VERSION ""

NS_ :

BS_:

BU_: FrontBoard BackBoard Kvaser SteeringWheel TCU GPS ACULV Bamocar PDM

BO_ 3221225472 VECTOR__INDEPENDENT_SIG_MSG: 0 Vector__XXX
 SG_ NewSignal_0009 : 0|8@1+ (1,0) [0|0] "" Vector__XXX
 SG_ Frequency1 : 0|64@1- (1,0) [0|0] ""  FrontBoard,Kvaser,SteeringWheel
 SG_ Frequency2 : 64|64@1- (1,0) [0|0] ""  FrontBoard,Kvaser,SteeringWheel
 SG_ Frequency3 : 128|64@1- (1,0) [0|0] ""  FrontBoard,Kvaser,SteeringWheel
 SG_ Frequency4 : 192|64@1- (1,0) [0|0] ""  FrontBoard,Kvaser,SteeringWheel
 SG_ Frequency1 : 0|64@1- (1,0) [0|0] ""  BackBoard,Kvaser,SteeringWheel
 SG_ Frequency2 : 64|64@1- (1,0) [0|0] ""  BackBoard,Kvaser,SteeringWheel
 SG_ Frequency3 : 128|64@1- (1,0) [0|0] ""  BackBoard,Kvaser,SteeringWheel
 SG_ Frequency4 : 192|64@1- (1,0) [0|0] ""  BackBoard,Kvaser,SteeringWheel
 SG_ AccumulatorVoltage : 0|32@1- (1,0) [0|0] "" Vector__XXX
 SG_ TractiveVoltage : 0|32@1- (1,0) [0|0] "" Vector__XXX
 SG_ InputState_Diagnostics : 0|8@1+ (1,0) [0|0] "" Vector__XXX
 SG_ CompoundID : 0|8@1+ (1,0) [0|0] "" Vector__XXX
 SG_ DeviceInfo : 48|8@1+ (1,0) [0|0] "" Vector__XXX
 SG_ OutputLoad : 40|8@1+ (1,0) [0|0] "" Vector__XXX
 SG_ OutputCurrent : 32|8@1+ (1,0) [0|0] "" Vector__XXX
 SG_ OutputVoltage : 24|8@1+ (1,0) [0|0] "" Vector__XXX
 SG_ OutputState : 16|8@1+ (1,0) [0|0] "" Vector__XXX
 SG_ InputVoltage : 8|8@1+ (1,0) [0|0] "" Vector__XXX
 SG_ Byte2 : 0|8@1+ (1,0) [0|0] "" Vector__XXX
 SG_ Byte5 : 0|8@1+ (1,0) [0|0] "" Vector__XXX
 SG_ Byte4 : 0|8@1+ (1,0) [0|0] "" Vector__XXX
 SG_ Byte3 : 0|8@1+ (1,0) [0|0] "" Vector__XXX
 SG_ AirTemp : 0|32@1+ (1,0) [0|0] ""  Kvaser,SteeringWheel
 SG_ IGBTTemp : 0|32@1+ (1,0) [0|0] ""  Kvaser,SteeringWheel
 SG_ MotorTemp : 0|32@1+ (1,0) [0|0] ""  Kvaser,SteeringWheel

BO_ 259 FrontAnalog: 16 FrontBoard
 SG_ Analog1 : 0|16@1+ (1,0) [0|0] ""  FrontBoard,Kvaser,SteeringWheel
 SG_ Analog2 : 16|16@1+ (1,0) [0|0] ""  FrontBoard,Kvaser,SteeringWheel
 SG_ Analog3 : 32|16@1+ (1,0) [0|0] ""  FrontBoard,Kvaser,SteeringWheel
 SG_ Analog4 : 48|16@1+ (1,0) [0|0] ""  FrontBoard,Kvaser,SteeringWheel
 SG_ Analog5 : 64|16@1+ (1,0) [0|0] ""  FrontBoard,Kvaser,SteeringWheel
 SG_ Analog6 : 80|16@1+ (1,0) [0|0] ""  FrontBoard,Kvaser,SteeringWheel
 SG_ Analog7 : 96|16@1+ (1,0) [0|0] ""  FrontBoard,Kvaser,SteeringWheel
 SG_ Analog8 : 112|16@1+ (1,0) [0|0] ""  FrontBoard,Kvaser,SteeringWheel

BO_ 258 RearAnalog: 16 BackBoard
 SG_ Analog1 : 0|16@1+ (1,0) [0|0] ""  BackBoard,Kvaser,SteeringWheel
 SG_ Analog2 : 16|16@1+ (1,0) [0|0] ""  BackBoard,Kvaser,SteeringWheel
 SG_ Analog3 : 32|16@1+ (1,0) [0|0] ""  BackBoard,Kvaser,SteeringWheel
 SG_ Analog4 : 48|16@1+ (1,0) [0|0] ""  BackBoard,Kvaser,SteeringWheel
 SG_ Analog5 : 64|16@1+ (1,0) [0|0] ""  BackBoard,Kvaser,SteeringWheel
 SG_ Analog6 : 80|16@1+ (1,0) [0|0] ""  BackBoard,Kvaser,SteeringWheel
 SG_ Analog7 : 96|16@1+ (1,0) [0|0] ""  BackBoard,Kvaser,SteeringWheel
 SG_ Analog8 : 112|16@1+ (1,0) [0|0] ""  BackBoard,Kvaser,SteeringWheel

BO_ 1536 FrontAero: 16 FrontBoard
 SG_ Pressure1 : 0|24@1- (1,0) [0|0] ""  FrontBoard,Kvaser,SteeringWheel
 SG_ Pressure2 : 24|24@1- (1,0) [0|0] ""  FrontBoard,Kvaser,SteeringWheel
 SG_ Pressure3 : 48|24@1- (1,0) [0|0] ""  FrontBoard,Kvaser,SteeringWheel
 SG_ Temperature1 : 72|16@1- (1,0) [0|0] ""  FrontBoard,Kvaser,SteeringWheel
 SG_ Temperature2 : 88|16@1- (1,0) [0|0] ""  FrontBoard,Kvaser,SteeringWheel
 SG_ Temperature3 : 104|16@1- (1,0) [0|0] ""  FrontBoard,Kvaser,SteeringWheel

BO_ 1537 RearAero: 16 BackBoard
 SG_ Pressure1 : 0|24@1- (1,0) [0|0] ""  BackBoard,SteeringWheel,Kvaser
 SG_ Pressure2 : 24|24@1- (1,0) [0|0] ""  BackBoard,SteeringWheel,Kvaser
 SG_ Pressure3 : 48|24@1- (1,0) [0|0] ""  BackBoard,SteeringWheel,Kvaser
 SG_ Temperature1 : 72|16@1- (1,0) [0|0] ""  BackBoard,SteeringWheel,Kvaser
 SG_ Temperature2 : 88|16@1- (1,0) [0|0] ""  BackBoard,SteeringWheel,Kvaser
 SG_ Temperature3 : 104|16@1- (1,0) [0|0] ""  BackBoard,SteeringWheel,Kvaser

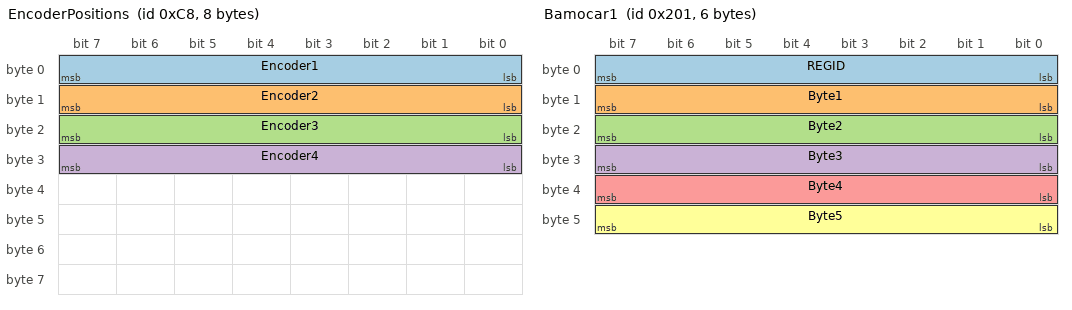
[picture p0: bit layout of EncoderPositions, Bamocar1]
BO_ 200 EncoderPositions: 8 SteeringWheel
 SG_ Encoder1 : 0|8@1+ (1,0) [0|0] ""  Kvaser
 SG_ Encoder2 : 8|8@1+ (1,0) [0|0] ""  Kvaser
 SG_ Encoder3 : 16|8@1+ (1,0) [0|0] ""  Kvaser
 SG_ Encoder4 : 24|8@1+ (1,0) [0|0] ""  Kvaser

BO_ 1552 FrontStrainGauges1: 20 FrontBoard
 SG_ Gauge1 : 0|24@1+ (1,0) [0|0] ""  Kvaser
 SG_ Gauge2 : 24|24@1+ (1,0) [0|0] ""  Kvaser
 SG_ Gauge3 : 48|24@1+ (1,0) [0|0] ""  Kvaser
 SG_ Gauge4 : 72|24@1+ (1,0) [0|0] ""  Kvaser
 SG_ Gauge5 : 96|24@1+ (1,0) [0|0] ""  Kvaser
 SG_ Gauge6 : 120|24@1+ (1,0) [0|0] ""  Kvaser

BO_ 1553 FrontStrainGauges2: 20 FrontBoard
 SG_ Gauge1 : 0|24@1+ (1,0) [0|0] ""  Kvaser
 SG_ Gauge2 : 24|24@1+ (1,0) [0|0] ""  Kvaser
 SG_ Gauge3 : 48|24@1+ (1,0) [0|0] ""  Kvaser
 SG_ Gauge4 : 72|24@1+ (1,0) [0|0] ""  Kvaser
 SG_ Gauge5 : 96|24@1+ (1,0) [0|0] ""  Kvaser
 SG_ Gauge6 : 120|24@1+ (1,0) [0|0] ""  Kvaser

BO_ 1554 RearStrainGauges1: 20 BackBoard
 SG_ Gauge1 : 0|24@1+ (1,0) [0|0] ""  Kvaser
 SG_ Gauge2 : 24|24@1+ (1,0) [0|0] ""  Kvaser
 SG_ Gauge3 : 48|24@1+ (1,0) [0|0] ""  Kvaser
 SG_ Gauge4 : 72|24@1+ (1,0) [0|0] ""  Kvaser
 SG_ Gauge5 : 96|24@1+ (1,0) [0|0] ""  Kvaser
 SG_ Gauge6 : 120|24@1+ (1,0) [0|0] ""  Kvaser

BO_ 1555 RearStrainGauges2: 20 BackBoard
 SG_ Gauge1 : 0|24@1+ (1,0) [0|0] ""  Kvaser
 SG_ Gauge2 : 24|24@1+ (1,0) [0|0] ""  Kvaser
 SG_ Gauge3 : 48|24@1+ (1,0) [0|0] ""  Kvaser
 SG_ Gauge4 : 72|24@1+ (1,0) [0|0] ""  Kvaser
 SG_ Gauge5 : 96|24@1+ (1,0) [0|0] ""  Kvaser
 SG_ Gauge6 : 120|24@1+ (1,0) [0|0] ""  Kvaser

BO_ 80 GPSBestPos: 48 GPS
 SG_ Latitude : 0|64@1- (1,0) [0|0] ""  Kvaser,SteeringWheel
 SG_ Longitude : 64|64@1- (1,0) [0|0] ""  Kvaser,SteeringWheel
 SG_ Altitude : 128|64@1- (1,0) [0|0] ""  Kvaser,SteeringWheel
 SG_ stdLatitude : 192|64@1- (1,0) [0|0] ""  Kvaser,SteeringWheel
 SG_ stdLongitude : 256|64@1- (1,0) [0|0] ""  Kvaser,SteeringWheel
 SG_ stdAltitude : 320|64@1- (1,0) [0|0] ""  Kvaser,SteeringWheel

BO_ 101 FrontFrequency: 16 FrontBoard
 SG_ Freq1 : 0|32@1- (1,0) [0|0] ""  Kvaser,SteeringWheel
 SG_ Freq2 : 32|32@1- (1,0) [0|0] ""  Kvaser,SteeringWheel
 SG_ Freq3 : 64|32@1- (1,0) [0|0] ""  Kvaser,SteeringWheel
 SG_ Freq4 : 96|32@1- (1,0) [0|0] ""  Kvaser,SteeringWheel

BO_ 102 RearFrequency: 16 BackBoard
 SG_ Freq1 : 0|32@1- (1,0) [0|0] ""  Kvaser,SteeringWheel
 SG_ Freq2 : 32|32@1- (1,0) [0|0] ""  Kvaser,SteeringWheel
 SG_ Freq3 : 64|32@1- (1,0) [0|0] ""  Kvaser,SteeringWheel
 SG_ Freq4 : 96|32@1- (1,0) [0|0] ""  Kvaser,SteeringWheel

BO_ 513 Bamocar1: 6 TCU
 SG_ REGID : 0|8@1- (1,0) [0|0] ""  Kvaser,SteeringWheel
 SG_ Byte1 : 8|8@1+ (1,0) [0|0] ""  Kvaser,SteeringWheel
 SG_ Byte2 : 16|8@1+ (1,0) [0|0] ""  Kvaser,SteeringWheel
 SG_ Byte3 : 24|8@1+ (1,0) [0|0] ""  Kvaser,SteeringWheel
 SG_ Byte4 : 32|8@1+ (1,0) [0|0] ""  Kvaser,SteeringWheel
 SG_ Byte5 : 40|8@1+ (1,0) [0|0] ""  Kvaser,SteeringWheel

BO_ 50 CellVoltage1: 64 ACULV
 SG_ Cell1 : 0|32@1- (1,0) [0|0] ""  Kvaser,SteeringWheel
 SG_ Cell2 : 32|32@1- (1,0) [0|0] ""  Kvaser,SteeringWheel
 SG_ Cell3 : 64|32@1- (1,0) [0|0] ""  Kvaser,SteeringWheel
 SG_ Cell4 : 96|32@1- (1,0) [0|0] ""  Kvaser,SteeringWheel
 SG_ Cell5 : 128|32@1- (1,0) [0|0] ""  Kvaser,SteeringWheel
 SG_ Cell6 : 160|32@1- (1,0) [0|0] ""  Kvaser,SteeringWheel
 SG_ Cell7 : 192|32@1- (1,0) [0|0] ""  Kvaser,SteeringWheel
 SG_ Cell8 : 224|32@1- (1,0) [0|0] ""  Kvaser,SteeringWheel
 SG_ Cell9 : 256|32@1- (1,0) [0|0] ""  Kvaser,SteeringWheel
 SG_ Cell10 : 288|32@1- (1,0) [0|0] ""  Kvaser,SteeringWheel
 SG_ Cell11 : 320|32@1- (1,0) [0|0] ""  Kvaser,SteeringWheel
 SG_ Cell12 : 352|32@1- (1,0) [0|0] ""  Kvaser,SteeringWheel
 SG_ Cell13 : 384|32@1- (1,0) [0|0] ""  Kvaser,SteeringWheel
 SG_ Cell14 : 416|32@1- (1,0) [0|0] ""  Kvaser,SteeringWheel
 SG_ Cell15 : 448|32@1- (1,0) [0|0] ""  Kvaser,SteeringWheel
 SG_ Cell16 : 480|32@1- (1,0) [0|0] ""  Kvaser,SteeringWheel

BO_ 51 CellVoltage2: 64 ACULV
 SG_ Cell1 : 0|32@1- (1,0) [0|0] ""  Kvaser,SteeringWheel
 SG_ Cell2 : 32|32@1- (1,0) [0|0] ""  Kvaser,SteeringWheel
 SG_ Cell3 : 64|32@1- (1,0) [0|0] ""  Kvaser,SteeringWheel
 SG_ Cell4 : 96|32@1- (1,0) [0|0] ""  Kvaser,SteeringWheel
 SG_ Cell5 : 128|32@1- (1,0) [0|0] ""  Kvaser,SteeringWheel
 SG_ Cell6 : 160|32@1- (1,0) [0|0] ""  Kvaser,SteeringWheel
 SG_ Cell7 : 192|32@1- (1,0) [0|0] ""  Kvaser,SteeringWheel
 SG_ Cell8 : 224|32@1- (1,0) [0|0] ""  Kvaser,SteeringWheel
 SG_ Cell9 : 256|32@1- (1,0) [0|0] ""  Kvaser,SteeringWheel
 SG_ Cell10 : 288|32@1- (1,0) [0|0] ""  Kvaser,SteeringWheel
 SG_ Cell11 : 320|32@1- (1,0) [0|0] ""  Kvaser,SteeringWheel
 SG_ Cell12 : 352|32@1- (1,0) [0|0] ""  Kvaser,SteeringWheel
 SG_ Cell13 : 384|32@1- (1,0) [0|0] ""  Kvaser,SteeringWheel
 SG_ Cell14 : 416|32@1- (1,0) [0|0] ""  Kvaser,SteeringWheel
 SG_ Cell15 : 448|32@1- (1,0) [0|0] ""  Kvaser,SteeringWheel
 SG_ Cell16 : 480|32@1- (1,0) [0|0] ""  Kvaser,SteeringWheel

BO_ 52 CellVoltage3: 64 ACULV
 SG_ Cell1 : 0|32@1- (1,0) [0|0] ""  Kvaser,SteeringWheel
 SG_ Cell2 : 32|32@1- (1,0) [0|0] ""  Kvaser,SteeringWheel
 SG_ Cell3 : 64|32@1- (1,0) [0|0] ""  Kvaser,SteeringWheel
 SG_ Cell4 : 96|32@1- (1,0) [0|0] ""  Kvaser,SteeringWheel
 SG_ Cell5 : 128|32@1- (1,0) [0|0] ""  Kvaser,SteeringWheel
 SG_ Cell6 : 160|32@1- (1,0) [0|0] ""  Kvaser,SteeringWheel
 SG_ Cell7 : 192|32@1- (1,0) [0|0] ""  Kvaser,SteeringWheel
 SG_ Cell8 : 224|32@1- (1,0) [0|0] ""  Kvaser,SteeringWheel
 SG_ Cell9 : 256|32@1- (1,0) [0|0] ""  Kvaser,SteeringWheel
 SG_ Cell10 : 288|32@1- (1,0) [0|0] ""  Kvaser,SteeringWheel
 SG_ Cell11 : 320|32@1- (1,0) [0|0] ""  Kvaser,SteeringWheel
 SG_ Cell12 : 352|32@1- (1,0) [0|0] ""  Kvaser,SteeringWheel
 SG_ Cell13 : 384|32@1- (1,0) [0|0] ""  Kvaser,SteeringWheel
 SG_ Cell14 : 416|32@1- (1,0) [0|0] ""  Kvaser,SteeringWheel
 SG_ Cell15 : 448|32@1- (1,0) [0|0] ""  Kvaser,SteeringWheel
 SG_ Cell16 : 480|32@1- (1,0) [0|0] ""  Kvaser,SteeringWheel

BO_ 53 CellVoltage4: 64 ACULV
 SG_ Cell1 : 0|32@1- (1,0) [0|0] ""  Kvaser,SteeringWheel
 SG_ Cell2 : 32|32@1- (1,0) [0|0] ""  Kvaser,SteeringWheel
 SG_ Cell3 : 64|32@1- (1,0) [0|0] ""  Kvaser,SteeringWheel
 SG_ Cell4 : 96|32@1- (1,0) [0|0] ""  Kvaser,SteeringWheel
 SG_ Cell5 : 128|32@1- (1,0) [0|0] ""  Kvaser,SteeringWheel
 SG_ Cell6 : 160|32@1- (1,0) [0|0] ""  Kvaser,SteeringWheel
 SG_ Cell7 : 192|32@1- (1,0) [0|0] ""  Kvaser,SteeringWheel
 SG_ Cell8 : 224|32@1- (1,0) [0|0] ""  Kvaser,SteeringWheel
 SG_ Cell9 : 256|32@1- (1,0) [0|0] ""  Kvaser,SteeringWheel
 SG_ Cell10 : 288|32@1- (1,0) [0|0] ""  Kvaser,SteeringWheel
 SG_ Cell11 : 320|32@1- (1,0) [0|0] ""  Kvaser,SteeringWheel
 SG_ Cell12 : 352|32@1- (1,0) [0|0] ""  Kvaser,SteeringWheel
 SG_ Cell13 : 384|32@1- (1,0) [0|0] ""  Kvaser,SteeringWheel
 SG_ Cell14 : 416|32@1- (1,0) [0|0] ""  Kvaser,SteeringWheel
 SG_ Cell15 : 448|32@1- (1,0) [0|0] ""  Kvaser,SteeringWheel
 SG_ Cell16 : 480|32@1- (1,0) [0|0] ""  Kvaser,SteeringWheel

BO_ 54 CellVoltage5: 64 ACULV
 SG_ Cell1 : 0|32@1- (1,0) [0|0] ""  Kvaser,SteeringWheel
 SG_ Cell2 : 32|32@1- (1,0) [0|0] ""  Kvaser,SteeringWheel
 SG_ Cell3 : 64|32@1- (1,0) [0|0] ""  Kvaser,SteeringWheel
 SG_ Cell4 : 96|32@1- (1,0) [0|0] ""  Kvaser,SteeringWheel
 SG_ Cell5 : 128|32@1- (1,0) [0|0] ""  Kvaser,SteeringWheel
 SG_ Cell6 : 160|32@1- (1,0) [0|0] ""  Kvaser,SteeringWheel
 SG_ Cell7 : 192|32@1- (1,0) [0|0] ""  Kvaser,SteeringWheel
 SG_ Cell8 : 224|32@1- (1,0) [0|0] ""  Kvaser,SteeringWheel
 SG_ Cell9 : 256|32@1- (1,0) [0|0] ""  Kvaser,SteeringWheel
 SG_ Cell10 : 288|32@1- (1,0) [0|0] ""  Kvaser,SteeringWheel
 SG_ Cell11 : 320|32@1- (1,0) [0|0] ""  Kvaser,SteeringWheel
 SG_ Cell12 : 352|32@1- (1,0) [0|0] ""  Kvaser,SteeringWheel
 SG_ Cell13 : 384|32@1- (1,0) [0|0] ""  Kvaser,SteeringWheel
 SG_ Cell14 : 416|32@1- (1,0) [0|0] ""  Kvaser,SteeringWheel
 SG_ Cell15 : 448|32@1- (1,0) [0|0] ""  Kvaser,SteeringWheel
 SG_ Cell16 : 480|32@1- (1,0) [0|0] ""  Kvaser,SteeringWheel

BO_ 55 CellVoltage6: 64 ACULV
 SG_ Cell1 : 0|32@1- (1,0) [0|0] ""  Kvaser,SteeringWheel
 SG_ Cell2 : 32|32@1- (1,0) [0|0] ""  Kvaser,SteeringWheel
 SG_ Cell3 : 64|32@1- (1,0) [0|0] ""  Kvaser,SteeringWheel
 SG_ Cell4 : 96|32@1- (1,0) [0|0] ""  Kvaser,SteeringWheel
 SG_ Cell5 : 128|32@1- (1,0) [0|0] ""  Kvaser,SteeringWheel
 SG_ Cell6 : 160|32@1- (1,0) [0|0] ""  Kvaser,SteeringWheel
 SG_ Cell7 : 192|32@1- (1,0) [0|0] ""  Kvaser,SteeringWheel
 SG_ Cell8 : 224|32@1- (1,0) [0|0] ""  Kvaser,SteeringWheel
 SG_ Cell9 : 256|32@1- (1,0) [0|0] ""  Kvaser,SteeringWheel
 SG_ Cell10 : 288|32@1- (1,0) [0|0] ""  Kvaser,SteeringWheel
 SG_ Cell11 : 320|32@1- (1,0) [0|0] ""  Kvaser,SteeringWheel
 SG_ Cell12 : 352|32@1- (1,0) [0|0] ""  Kvaser,SteeringWheel
 SG_ Cell13 : 384|32@1- (1,0) [0|0] ""  Kvaser,SteeringWheel
 SG_ Cell14 : 416|32@1- (1,0) [0|0] ""  Kvaser,SteeringWheel
 SG_ Cell15 : 448|32@1- (1,0) [0|0] ""  Kvaser,SteeringWheel
 SG_ Cell16 : 480|32@1- (1,0) [0|0] ""  Kvaser,SteeringWheel

BO_ 56 CellVoltage7: 64 ACULV
 SG_ Cell1 : 0|32@1- (1,0) [0|0] ""  Kvaser,SteeringWheel
 SG_ Cell2 : 32|32@1- (1,0) [0|0] ""  Kvaser,SteeringWheel
 SG_ Cell3 : 64|32@1- (1,0) [0|0] ""  Kvaser,SteeringWheel
 SG_ Cell4 : 96|32@1- (1,0) [0|0] ""  Kvaser,SteeringWheel
 SG_ Cell5 : 128|32@1- (1,0) [0|0] ""  Kvaser,SteeringWheel
 SG_ Cell6 : 160|32@1- (1,0) [0|0] ""  Kvaser,SteeringWheel
 SG_ Cell7 : 192|32@1- (1,0) [0|0] ""  Kvaser,SteeringWheel
 SG_ Cell8 : 224|32@1- (1,0) [0|0] ""  Kvaser,SteeringWheel
 SG_ Cell9 : 256|32@1- (1,0) [0|0] ""  Kvaser,SteeringWheel
 SG_ Cell10 : 288|32@1- (1,0) [0|0] ""  Kvaser,SteeringWheel
 SG_ Cell11 : 320|32@1- (1,0) [0|0] ""  Kvaser,SteeringWheel
 SG_ Cell12 : 352|32@1- (1,0) [0|0] ""  Kvaser,SteeringWheel
 SG_ Cell13 : 384|32@1- (1,0) [0|0] ""  Kvaser,SteeringWheel
 SG_ Cell14 : 416|32@1- (1,0) [0|0] ""  Kvaser,SteeringWheel
 SG_ Cell15 : 448|32@1- (1,0) [0|0] ""  Kvaser,SteeringWheel
 SG_ Cell16 : 480|32@1- (1,0) [0|0] ""  Kvaser,SteeringWheel

BO_ 57 CellVoltage8: 64 ACULV
 SG_ Cell1 : 0|32@1- (1,0) [0|0] ""  Kvaser,SteeringWheel
 SG_ Cell2 : 32|32@1- (1,0) [0|0] ""  Kvaser,SteeringWheel
 SG_ Cell3 : 64|32@1- (1,0) [0|0] ""  Kvaser,SteeringWheel
 SG_ Cell4 : 96|32@1- (1,0) [0|0] ""  Kvaser,SteeringWheel
 SG_ Cell5 : 128|32@1- (1,0) [0|0] ""  Kvaser,SteeringWheel
 SG_ Cell6 : 160|32@1- (1,0) [0|0] ""  Kvaser,SteeringWheel
 SG_ Cell7 : 192|32@1- (1,0) [0|0] ""  Kvaser,SteeringWheel
 SG_ Cell8 : 224|32@1- (1,0) [0|0] ""  Kvaser,SteeringWheel
 SG_ Cell9 : 256|32@1- (1,0) [0|0] ""  Kvaser,SteeringWheel
 SG_ Cell10 : 288|32@1- (1,0) [0|0] ""  Kvaser,SteeringWheel
 SG_ Cell11 : 320|32@1- (1,0) [0|0] ""  Kvaser,SteeringWheel
 SG_ Cell12 : 352|32@1- (1,0) [0|0] ""  Kvaser,SteeringWheel
 SG_ Cell13 : 384|32@1- (1,0) [0|0] ""  Kvaser,SteeringWheel
 SG_ Cell14 : 416|32@1- (1,0) [0|0] ""  Kvaser,SteeringWheel
 SG_ Cell15 : 448|32@1- (1,0) [0|0] ""  Kvaser,SteeringWheel
 SG_ Cell16 : 480|32@1- (1,0) [0|0] ""  Kvaser,SteeringWheel

BO_ 60 Thermistor1: 64 ACULV
 SG_ Therm1 : 0|32@1- (1,0) [0|0] ""  Kvaser,SteeringWheel
 SG_ Therm2 : 32|32@1- (1,0) [0|0] ""  Kvaser,SteeringWheel
 SG_ Therm3 : 64|32@1- (1,0) [0|0] ""  Kvaser,SteeringWheel
 SG_ Therm4 : 96|32@1- (1,0) [0|0] ""  Kvaser,SteeringWheel
 SG_ Therm5 : 128|32@1- (1,0) [0|0] ""  Kvaser,SteeringWheel
 SG_ Therm6 : 160|32@1- (1,0) [0|0] ""  Kvaser,SteeringWheel
 SG_ Therm7 : 192|32@1- (1,0) [0|0] ""  Kvaser,SteeringWheel
 SG_ Therm8 : 224|32@1- (1,0) [0|0] ""  Kvaser,SteeringWheel
 SG_ Therm9 : 256|32@1- (1,0) [0|0] ""  Kvaser,SteeringWheel
 SG_ Therm10 : 288|32@1- (1,0) [0|0] ""  Kvaser,SteeringWheel
 SG_ Therm11 : 320|32@1- (1,0) [0|0] ""  Kvaser,SteeringWheel
 SG_ Therm12 : 352|32@1- (1,0) [0|0] ""  Kvaser,SteeringWheel
 SG_ Therm13 : 384|32@1- (1,0) [0|0] ""  Kvaser,SteeringWheel
 SG_ Therm14 : 416|32@1- (1,0) [0|0] ""  Kvaser,SteeringWheel
 SG_ Therm15 : 448|32@1- (1,0) [0|0] ""  Kvaser,SteeringWheel
 SG_ Therm16 : 480|32@1- (1,0) [0|0] ""  Kvaser,SteeringWheel

BO_ 61 Thermistor2: 64 ACULV
 SG_ Therm1 : 0|32@1- (1,0) [0|0] ""  Kvaser,SteeringWheel
 SG_ Therm2 : 32|32@1- (1,0) [0|0] ""  Kvaser,SteeringWheel
 SG_ Therm3 : 64|32@1- (1,0) [0|0] ""  Kvaser,SteeringWheel
 SG_ Therm4 : 96|32@1- (1,0) [0|0] ""  Kvaser,SteeringWheel
 SG_ Therm5 : 128|32@1- (1,0) [0|0] ""  Kvaser,SteeringWheel
 SG_ Therm6 : 160|32@1- (1,0) [0|0] ""  Kvaser,SteeringWheel
 SG_ Therm7 : 192|32@1- (1,0) [0|0] ""  Kvaser,SteeringWheel
 SG_ Therm8 : 224|32@1- (1,0) [0|0] ""  Kvaser,SteeringWheel
 SG_ Therm9 : 256|32@1- (1,0) [0|0] ""  Kvaser,SteeringWheel
 SG_ Therm10 : 288|32@1- (1,0) [0|0] ""  Kvaser,SteeringWheel
 SG_ Therm11 : 320|32@1- (1,0) [0|0] ""  Kvaser,SteeringWheel
 SG_ Therm12 : 352|32@1- (1,0) [0|0] ""  Kvaser,SteeringWheel
 SG_ Therm13 : 384|32@1- (1,0) [0|0] ""  Kvaser,SteeringWheel
 SG_ Therm14 : 416|32@1- (1,0) [0|0] ""  Kvaser,SteeringWheel
 SG_ Therm15 : 448|32@1- (1,0) [0|0] ""  Kvaser,SteeringWheel
 SG_ Therm16 : 480|32@1- (1,0) [0|0] ""  Kvaser,SteeringWheel

BO_ 62 Thermistor3: 64 ACULV
 SG_ Therm1 : 0|32@1- (1,0) [0|0] ""  Kvaser,SteeringWheel
 SG_ Therm2 : 32|32@1- (1,0) [0|0] ""  Kvaser,SteeringWheel
 SG_ Therm3 : 64|32@1- (1,0) [0|0] ""  Kvaser,SteeringWheel
 SG_ Therm4 : 96|32@1- (1,0) [0|0] ""  Kvaser,SteeringWheel
 SG_ Therm5 : 128|32@1- (1,0) [0|0] ""  Kvaser,SteeringWheel
 SG_ Therm6 : 160|32@1- (1,0) [0|0] ""  Kvaser,SteeringWheel
 SG_ Therm7 : 192|32@1- (1,0) [0|0] ""  Kvaser,SteeringWheel
 SG_ Therm8 : 224|32@1- (1,0) [0|0] ""  Kvaser,SteeringWheel
 SG_ Therm9 : 256|32@1- (1,0) [0|0] ""  Kvaser,SteeringWheel
 SG_ Therm10 : 288|32@1- (1,0) [0|0] ""  Kvaser,SteeringWheel
 SG_ Therm11 : 320|32@1- (1,0) [0|0] ""  Kvaser,SteeringWheel
 SG_ Therm12 : 352|32@1- (1,0) [0|0] ""  Kvaser,SteeringWheel
 SG_ Therm13 : 384|32@1- (1,0) [0|0] ""  Kvaser,SteeringWheel
 SG_ Therm14 : 416|32@1- (1,0) [0|0] ""  Kvaser,SteeringWheel
 SG_ Therm15 : 448|32@1- (1,0) [0|0] ""  Kvaser,SteeringWheel
 SG_ Therm16 : 480|32@1- (1,0) [0|0] ""  Kvaser,SteeringWheel

BO_ 63 Thermistor4: 64 ACULV
 SG_ Therm1 : 0|32@1- (1,0) [0|0] ""  Kvaser,SteeringWheel
 SG_ Therm2 : 32|32@1- (1,0) [0|0] ""  Kvaser,SteeringWheel
 SG_ Therm3 : 64|32@1- (1,0) [0|0] ""  Kvaser,SteeringWheel
 SG_ Therm4 : 96|32@1- (1,0) [0|0] ""  Kvaser,SteeringWheel
 SG_ Therm5 : 128|32@1- (1,0) [0|0] ""  Kvaser,SteeringWheel
 SG_ Therm6 : 160|32@1- (1,0) [0|0] ""  Kvaser,SteeringWheel
 SG_ Therm7 : 192|32@1- (1,0) [0|0] ""  Kvaser,SteeringWheel
 SG_ Therm8 : 224|32@1- (1,0) [0|0] ""  Kvaser,SteeringWheel
 SG_ Therm9 : 256|32@1- (1,0) [0|0] ""  Kvaser,SteeringWheel
 SG_ Therm10 : 288|32@1- (1,0) [0|0] ""  Kvaser,SteeringWheel
 SG_ Therm11 : 320|32@1- (1,0) [0|0] ""  Kvaser,SteeringWheel
 SG_ Therm12 : 352|32@1- (1,0) [0|0] ""  Kvaser,SteeringWheel
 SG_ Therm13 : 384|32@1- (1,0) [0|0] ""  Kvaser,SteeringWheel
 SG_ Therm14 : 416|32@1- (1,0) [0|0] ""  Kvaser,SteeringWheel
 SG_ Therm15 : 448|32@1- (1,0) [0|0] ""  Kvaser,SteeringWheel
 SG_ Therm16 : 480|32@1- (1,0) [0|0] ""  Kvaser,SteeringWheel

BO_ 64 Thermistor5: 64 ACULV
 SG_ Therm1 : 0|32@1- (1,0) [0|0] ""  Kvaser,SteeringWheel
 SG_ Therm2 : 32|32@1- (1,0) [0|0] ""  Kvaser,SteeringWheel
 SG_ Therm3 : 64|32@1- (1,0) [0|0] ""  Kvaser,SteeringWheel
 SG_ Therm4 : 96|32@1- (1,0) [0|0] ""  Kvaser,SteeringWheel
 SG_ Therm5 : 128|32@1- (1,0) [0|0] ""  Kvaser,SteeringWheel
 SG_ Therm6 : 160|32@1- (1,0) [0|0] ""  Kvaser,SteeringWheel
 SG_ Therm7 : 192|32@1- (1,0) [0|0] ""  Kvaser,SteeringWheel
 SG_ Therm8 : 224|32@1- (1,0) [0|0] ""  Kvaser,SteeringWheel
 SG_ Therm9 : 256|32@1- (1,0) [0|0] ""  Kvaser,SteeringWheel
 SG_ Therm10 : 288|32@1- (1,0) [0|0] ""  Kvaser,SteeringWheel
 SG_ Therm11 : 320|32@1- (1,0) [0|0] ""  Kvaser,SteeringWheel
 SG_ Therm12 : 352|32@1- (1,0) [0|0] ""  Kvaser,SteeringWheel
 SG_ Therm13 : 384|32@1- (1,0) [0|0] ""  Kvaser,SteeringWheel
 SG_ Therm14 : 416|32@1- (1,0) [0|0] ""  Kvaser,SteeringWheel
 SG_ Therm15 : 448|32@1- (1,0) [0|0] ""  Kvaser,SteeringWheel
 SG_ Therm16 : 480|32@1- (1,0) [0|0] ""  Kvaser,SteeringWheel

BO_ 65 Thermistor6: 64 ACULV
 SG_ Therm1 : 0|32@1- (1,0) [0|0] ""  Kvaser,SteeringWheel
 SG_ Therm2 : 32|32@1- (1,0) [0|0] ""  Kvaser,SteeringWheel
 SG_ Therm3 : 64|32@1- (1,0) [0|0] ""  Kvaser,SteeringWheel
 SG_ Therm4 : 96|32@1- (1,0) [0|0] ""  Kvaser,SteeringWheel
 SG_ Therm5 : 128|32@1- (1,0) [0|0] ""  Kvaser,SteeringWheel
 SG_ Therm6 : 160|32@1- (1,0) [0|0] ""  Kvaser,SteeringWheel
 SG_ Therm7 : 192|32@1- (1,0) [0|0] ""  Kvaser,SteeringWheel
 SG_ Therm8 : 224|32@1- (1,0) [0|0] ""  Kvaser,SteeringWheel
 SG_ Therm9 : 256|32@1- (1,0) [0|0] ""  Kvaser,SteeringWheel
 SG_ Therm10 : 288|32@1- (1,0) [0|0] ""  Kvaser,SteeringWheel
 SG_ Therm11 : 320|32@1- (1,0) [0|0] ""  Kvaser,SteeringWheel
 SG_ Therm12 : 352|32@1- (1,0) [0|0] ""  Kvaser,SteeringWheel
 SG_ Therm13 : 384|32@1- (1,0) [0|0] ""  Kvaser,SteeringWheel
 SG_ Therm14 : 416|32@1- (1,0) [0|0] ""  Kvaser,SteeringWheel
 SG_ Therm15 : 448|32@1- (1,0) [0|0] ""  Kvaser,SteeringWheel
 SG_ Therm16 : 480|32@1- (1,0) [0|0] ""  Kvaser,SteeringWheel

BO_ 66 Thermistor7: 64 ACULV
 SG_ Therm1 : 0|32@1- (1,0) [0|0] ""  Kvaser,SteeringWheel
 SG_ Therm2 : 32|32@1- (1,0) [0|0] ""  Kvaser,SteeringWheel
 SG_ Therm3 : 64|32@1- (1,0) [0|0] ""  Kvaser,SteeringWheel
 SG_ Therm4 : 96|32@1- (1,0) [0|0] ""  Kvaser,SteeringWheel
 SG_ Therm5 : 128|32@1- (1,0) [0|0] ""  Kvaser,SteeringWheel
 SG_ Therm6 : 160|32@1- (1,0) [0|0] ""  Kvaser,SteeringWheel
 SG_ Therm7 : 192|32@1- (1,0) [0|0] ""  Kvaser,SteeringWheel
 SG_ Therm8 : 224|32@1- (1,0) [0|0] ""  Kvaser,SteeringWheel
 SG_ Therm9 : 256|32@1- (1,0) [0|0] ""  Kvaser,SteeringWheel
 SG_ Therm10 : 288|32@1- (1,0) [0|0] ""  Kvaser,SteeringWheel
 SG_ Therm11 : 320|32@1- (1,0) [0|0] ""  Kvaser,SteeringWheel
 SG_ Therm12 : 352|32@1- (1,0) [0|0] ""  Kvaser,SteeringWheel
 SG_ Therm13 : 384|32@1- (1,0) [0|0] ""  Kvaser,SteeringWheel
 SG_ Therm14 : 416|32@1- (1,0) [0|0] ""  Kvaser,SteeringWheel
 SG_ Therm15 : 448|32@1- (1,0) [0|0] ""  Kvaser,SteeringWheel
 SG_ Therm16 : 480|32@1- (1,0) [0|0] ""  Kvaser,SteeringWheel

BO_ 67 Thermistor8: 64 ACULV
 SG_ Therm1 : 0|32@1- (1,0) [0|0] ""  Kvaser,SteeringWheel
 SG_ Therm2 : 32|32@1- (1,0) [0|0] ""  Kvaser,SteeringWheel
 SG_ Therm3 : 64|32@1- (1,0) [0|0] ""  Kvaser,SteeringWheel
 SG_ Therm4 : 96|32@1- (1,0) [0|0] ""  Kvaser,SteeringWheel
 SG_ Therm5 : 128|32@1- (1,0) [0|0] ""  Kvaser,SteeringWheel
 SG_ Therm6 : 160|32@1- (1,0) [0|0] ""  Kvaser,SteeringWheel
 SG_ Therm7 : 192|32@1- (1,0) [0|0] ""  Kvaser,SteeringWheel
 SG_ Therm8 : 224|32@1- (1,0) [0|0] ""  Kvaser,SteeringWheel
 SG_ Therm9 : 256|32@1- (1,0) [0|0] ""  Kvaser,SteeringWheel
 SG_ Therm10 : 288|32@1- (1,0) [0|0] ""  Kvaser,SteeringWheel
 SG_ Therm11 : 320|32@1- (1,0) [0|0] ""  Kvaser,SteeringWheel
 SG_ Therm12 : 352|32@1- (1,0) [0|0] ""  Kvaser,SteeringWheel
 SG_ Therm13 : 384|32@1- (1,0) [0|0] ""  Kvaser,SteeringWheel
 SG_ Therm14 : 416|32@1- (1,0) [0|0] ""  Kvaser,SteeringWheel
 SG_ Therm15 : 448|32@1- (1,0) [0|0] ""  Kvaser,SteeringWheel
 SG_ Therm16 : 480|32@1- (1,0) [0|0] ""  Kvaser,SteeringWheel

BO_ 68 Thermistor9: 64 ACULV
 SG_ Therm1 : 0|32@1- (1,0) [0|0] ""  Kvaser,SteeringWheel
 SG_ Therm2 : 32|32@1- (1,0) [0|0] ""  Kvaser,SteeringWheel
 SG_ Therm3 : 64|32@1- (1,0) [0|0] ""  Kvaser,SteeringWheel
 SG_ Therm4 : 96|32@1- (1,0) [0|0] ""  Kvaser,SteeringWheel
 SG_ Therm5 : 128|32@1- (1,0) [0|0] ""  Kvaser,SteeringWheel
 SG_ Therm6 : 160|32@1- (1,0) [0|0] ""  Kvaser,SteeringWheel
 SG_ Therm7 : 192|32@1- (1,0) [0|0] ""  Kvaser,SteeringWheel
 SG_ Therm8 : 224|32@1- (1,0) [0|0] ""  Kvaser,SteeringWheel
 SG_ Therm9 : 256|32@1- (1,0) [0|0] ""  Kvaser,SteeringWheel
 SG_ Therm10 : 288|32@1- (1,0) [0|0] ""  Kvaser,SteeringWheel
 SG_ Therm11 : 320|32@1- (1,0) [0|0] ""  Kvaser,SteeringWheel
 SG_ Therm12 : 352|32@1- (1,0) [0|0] ""  Kvaser,SteeringWheel
 SG_ Therm13 : 384|32@1- (1,0) [0|0] ""  Kvaser,SteeringWheel
 SG_ Therm14 : 416|32@1- (1,0) [0|0] ""  Kvaser,SteeringWheel
 SG_ Therm15 : 448|32@1- (1,0) [0|0] ""  Kvaser,SteeringWheel
 SG_ Therm16 : 480|32@1- (1,0) [0|0] ""  Kvaser,SteeringWheel

BO_ 69 Thermistor10: 64 ACULV
 SG_ Therm1 : 0|32@1- (1,0) [0|0] ""  Kvaser,SteeringWheel
 SG_ Therm2 : 32|32@1- (1,0) [0|0] ""  Kvaser,SteeringWheel
 SG_ Therm3 : 64|32@1- (1,0) [0|0] ""  Kvaser,SteeringWheel
 SG_ Therm4 : 96|32@1- (1,0) [0|0] ""  Kvaser,SteeringWheel
 SG_ Therm5 : 128|32@1- (1,0) [0|0] ""  Kvaser,SteeringWheel
 SG_ Therm6 : 160|32@1- (1,0) [0|0] ""  Kvaser,SteeringWheel
 SG_ Therm7 : 192|32@1- (1,0) [0|0] ""  Kvaser,SteeringWheel
 SG_ Therm8 : 224|32@1- (1,0) [0|0] ""  Kvaser,SteeringWheel
 SG_ Therm9 : 256|32@1- (1,0) [0|0] ""  Kvaser,SteeringWheel
 SG_ Therm10 : 288|32@1- (1,0) [0|0] ""  Kvaser,SteeringWheel
 SG_ Therm11 : 320|32@1- (1,0) [0|0] ""  Kvaser,SteeringWheel
 SG_ Therm12 : 352|32@1- (1,0) [0|0] ""  Kvaser,SteeringWheel
 SG_ Therm13 : 384|32@1- (1,0) [0|0] ""  Kvaser,SteeringWheel
 SG_ Therm14 : 416|32@1- (1,0) [0|0] ""  Kvaser,SteeringWheel
 SG_ Therm15 : 448|32@1- (1,0) [0|0] ""  Kvaser,SteeringWheel
 SG_ Therm16 : 480|32@1- (1,0) [0|0] ""  Kvaser,SteeringWheel

BO_ 70 Thermistor11: 64 ACULV
 SG_ Therm1 : 0|32@1- (1,0) [0|0] ""  Kvaser,SteeringWheel
 SG_ Therm2 : 32|32@1- (1,0) [0|0] ""  Kvaser,SteeringWheel
 SG_ Therm3 : 64|32@1- (1,0) [0|0] ""  Kvaser,SteeringWheel
 SG_ Therm4 : 96|32@1- (1,0) [0|0] ""  Kvaser,SteeringWheel
 SG_ Therm5 : 128|32@1- (1,0) [0|0] ""  Kvaser,SteeringWheel
 SG_ Therm6 : 160|32@1- (1,0) [0|0] ""  Kvaser,SteeringWheel
 SG_ Therm7 : 192|32@1- (1,0) [0|0] ""  Kvaser,SteeringWheel
 SG_ Therm8 : 224|32@1- (1,0) [0|0] ""  Kvaser,SteeringWheel
 SG_ Therm9 : 256|32@1- (1,0) [0|0] ""  Kvaser,SteeringWheel
 SG_ Therm10 : 288|32@1- (1,0) [0|0] ""  Kvaser,SteeringWheel
 SG_ Therm11 : 320|32@1- (1,0) [0|0] ""  Kvaser,SteeringWheel
 SG_ Therm12 : 352|32@1- (1,0) [0|0] ""  Kvaser,SteeringWheel
 SG_ Therm13 : 384|32@1- (1,0) [0|0] ""  Kvaser,SteeringWheel
 SG_ Therm14 : 416|32@1- (1,0) [0|0] ""  Kvaser,SteeringWheel
 SG_ Therm15 : 448|32@1- (1,0) [0|0] ""  Kvaser,SteeringWheel
 SG_ Therm16 : 480|32@1- (1,0) [0|0] ""  Kvaser,SteeringWheel

BO_ 71 Thermistor12: 64 ACULV
 SG_ Therm1 : 0|32@1- (1,0) [0|0] ""  Kvaser,SteeringWheel
 SG_ Therm2 : 32|32@1- (1,0) [0|0] ""  Kvaser,SteeringWheel
 SG_ Therm3 : 64|32@1- (1,0) [0|0] ""  Kvaser,SteeringWheel
 SG_ Therm4 : 96|32@1- (1,0) [0|0] ""  Kvaser,SteeringWheel
 SG_ Therm5 : 128|32@1- (1,0) [0|0] ""  Kvaser,SteeringWheel
 SG_ Therm6 : 160|32@1- (1,0) [0|0] ""  Kvaser,SteeringWheel
 SG_ Therm7 : 192|32@1- (1,0) [0|0] ""  Kvaser,SteeringWheel
 SG_ Therm8 : 224|32@1- (1,0) [0|0] ""  Kvaser,SteeringWheel
 SG_ Therm9 : 256|32@1- (1,0) [0|0] ""  Kvaser,SteeringWheel
 SG_ Therm10 : 288|32@1- (1,0) [0|0] ""  Kvaser,SteeringWheel
 SG_ Therm11 : 320|32@1- (1,0) [0|0] ""  Kvaser,SteeringWheel
 SG_ Therm12 : 352|32@1- (1,0) [0|0] ""  Kvaser,SteeringWheel
 SG_ Therm13 : 384|32@1- (1,0) [0|0] ""  Kvaser,SteeringWheel
 SG_ Therm14 : 416|32@1- (1,0) [0|0] ""  Kvaser,SteeringWheel
 SG_ Therm15 : 448|32@1- (1,0) [0|0] ""  Kvaser,SteeringWheel
 SG_ Therm16 : 480|32@1- (1,0) [0|0] ""  Kvaser,SteeringWheel

BO_ 5 PackVoltage: 4 ACULV
 SG_ PackVoltage : 0|32@1- (1,0) [0|0] ""  Kvaser,SteeringWheel

BO_ 6 TCU1: 16 TCU
 SG_ APPS1 : 0|32@1- (1,0) [0|0] ""  Kvaser,SteeringWheel
 SG_ APPS2 : 32|32@1- (1,0) [0|0] ""  Kvaser,SteeringWheel
 SG_ BSE : 64|32@1- (1,0) [0|0] ""  Kvaser,SteeringWheel
 SG_ Status : 96|8@1+ (1,0) [0|0] ""  Kvaser,SteeringWheel

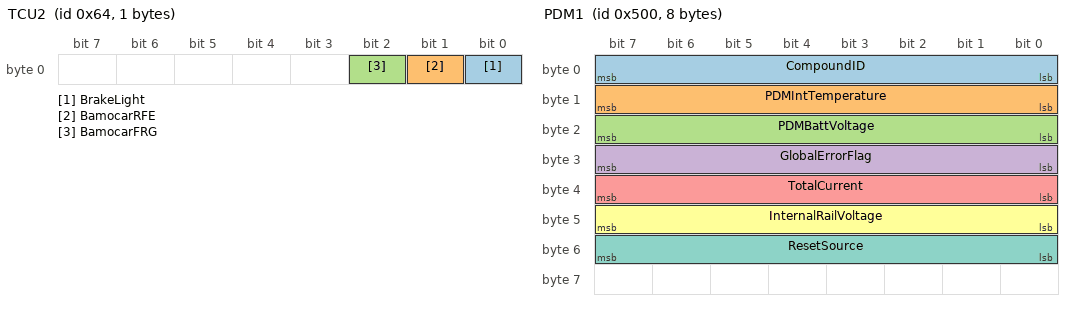
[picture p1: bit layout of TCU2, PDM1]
BO_ 100 TCU2: 1 TCU
 SG_ BrakeLight : 0|1@1+ (1,0) [0|0] ""  Kvaser,SteeringWheel
 SG_ BamocarRFE : 1|1@1+ (1,0) [0|0] ""  Kvaser,SteeringWheel
 SG_ BamocarFRG : 2|1@1+ (1,0) [0|0] ""  Kvaser,SteeringWheel

BO_ 8 ACULV_FD_1: 24 ACULV
 SG_ AMSStatus : 0|8@1+ (1,0) [0|0] ""  Kvaser,SteeringWheel
 SG_ FLD : 8|8@1+ (1,0) [0|0] ""  Kvaser,SteeringWheel
 SG_ StateOfCharge : 16|32@1- (1,0) [0|0] ""  Kvaser,SteeringWheel
 SG_ AccumulatorVoltage : 48|32@1- (1,0) [0|0] ""  Kvaser,SteeringWheel
 SG_ TractiveVoltage : 80|32@1- (1,0) [0|0] ""  Kvaser,SteeringWheel
 SG_ CellCurrent : 112|32@1- (1,0) [0|0] ""  Kvaser,SteeringWheel
 SG_ IsolationMonitoring : 144|8@1+ (1,0) [0|0] ""  Kvaser,SteeringWheel
 SG_ IsolationMonitoring1 : 152|32@1- (1,0) [0|0] ""  Kvaser,SteeringWheel

BO_ 30 ACULV_FD_2: 8 ACULV
 SG_ FanSetPoint : 0|32@1- (1,0) [0|0] ""  Kvaser,SteeringWheel
 SG_ RPM : 32|32@1- (1,0) [0|0] ""  Kvaser,SteeringWheel

BO_ 40 ACULV1: 8 ACULV
 SG_ ChargeStatus1 : 0|32@1- (1,0) [0|0] ""  Kvaser,SteeringWheel
 SG_ ChargeStatus2 : 32|32@1- (1,0) [0|0] ""  Kvaser,SteeringWheel

BO_ 41 ACULV2: 1 ACULV
 SG_ ChargeRequest : 0|8@1+ (1,0) [0|0] ""  Kvaser,SteeringWheel

BO_ 1280 PDM1: 8 PDM
 SG_ CompoundID : 0|8@1+ (1,0) [0|0] "" Vector__XXX
 SG_ PDMIntTemperature : 8|8@1+ (1,0) [0|125] "" Vector__XXX
 SG_ PDMBattVoltage : 16|8@1- (0.1216,0) [0|31] "" Vector__XXX
 SG_ GlobalErrorFlag : 24|8@1+ (1,0) [0|0] "" Vector__XXX
 SG_ TotalCurrent : 32|8@1+ (1,0) [0|255] "" Vector__XXX
 SG_ InternalRailVoltage : 40|8@1- (0.0615,0) [0|15.68] "" Vector__XXX
 SG_ ResetSource : 48|8@1+ (1,0) [0|0] "" Vector__XXX

CM_ SG_ 6 Status "RTD Button, Light, Status";
BA_DEF_  "BusType" STRING ;
BA_DEF_ BO_  "VFrameFormat" ENUM  "StandardCAN","ExtendedCAN","reserved","reserved","reserved","reserved","reserved","reserved","reserved","reserved","reserved","reserved","reserved","reserved","StandardCAN_FD","ExtendedCAN_FD";
BA_DEF_DEF_  "BusType" "";
BA_DEF_DEF_  "VFrameFormat" "StandardCAN";
BA_ "BusType" "CAN FD";
BA_ "VFrameFormat" BO_ 259 14;
BA_ "VFrameFormat" BO_ 258 14;
BA_ "VFrameFormat" BO_ 1536 14;
BA_ "VFrameFormat" BO_ 1537 14;
BA_ "VFrameFormat" BO_ 200 14;
BA_ "VFrameFormat" BO_ 1552 14;
BA_ "VFrameFormat" BO_ 1553 14;
BA_ "VFrameFormat" BO_ 1554 14;
BA_ "VFrameFormat" BO_ 1555 14;
BA_ "VFrameFormat" BO_ 80 14;
BA_ "VFrameFormat" BO_ 101 14;
BA_ "VFrameFormat" BO_ 102 14;
BA_ "VFrameFormat" BO_ 50 14;
BA_ "VFrameFormat" BO_ 51 14;
BA_ "VFrameFormat" BO_ 52 14;
BA_ "VFrameFormat" BO_ 53 14;
BA_ "VFrameFormat" BO_ 54 14;
BA_ "VFrameFormat" BO_ 55 14;
BA_ "VFrameFormat" BO_ 56 14;
BA_ "VFrameFormat" BO_ 57 14;
BA_ "VFrameFormat" BO_ 60 14;
BA_ "VFrameFormat" BO_ 61 14;
BA_ "VFrameFormat" BO_ 62 14;
BA_ "VFrameFormat" BO_ 63 14;
BA_ "VFrameFormat" BO_ 64 14;
BA_ "VFrameFormat" BO_ 65 14;
BA_ "VFrameFormat" BO_ 66 14;
BA_ "VFrameFormat" BO_ 67 14;
BA_ "VFrameFormat" BO_ 68 14;
BA_ "VFrameFormat" BO_ 69 14;
BA_ "VFrameFormat" BO_ 70 14;
BA_ "VFrameFormat" BO_ 71 14;
BA_ "VFrameFormat" BO_ 6 14;
BA_ "VFrameFormat" BO_ 100 14;
BA_ "VFrameFormat" BO_ 8 14;
BA_ "VFrameFormat" BO_ 30 14;
SIG_VALTYPE_ 80 Latitude : 2;
SIG_VALTYPE_ 80 Longitude : 2;
SIG_VALTYPE_ 80 Altitude : 2;
SIG_VALTYPE_ 80 stdLatitude : 2;
SIG_VALTYPE_ 80 stdLongitude : 2;
SIG_VALTYPE_ 80 stdAltitude : 2;
SIG_VALTYPE_ 101 Freq1 : 1;
SIG_VALTYPE_ 101 Freq2 : 1;
SIG_VALTYPE_ 101 Freq3 : 1;
SIG_VALTYPE_ 101 Freq4 : 1;
SIG_VALTYPE_ 102 Freq1 : 1;
SIG_VALTYPE_ 102 Freq2 : 1;
SIG_VALTYPE_ 102 Freq3 : 1;
SIG_VALTYPE_ 102 Freq4 : 1;
SIG_VALTYPE_ 50 Cell1 : 1;
SIG_VALTYPE_ 50 Cell2 : 1;
SIG_VALTYPE_ 50 Cell3 : 1;
SIG_VALTYPE_ 50 Cell4 : 1;
SIG_VALTYPE_ 50 Cell5 : 1;
SIG_VALTYPE_ 50 Cell6 : 1;
SIG_VALTYPE_ 50 Cell7 : 1;
SIG_VALTYPE_ 50 Cell8 : 1;
SIG_VALTYPE_ 50 Cell9 : 1;
SIG_VALTYPE_ 50 Cell10 : 1;
SIG_VALTYPE_ 50 Cell11 : 1;
SIG_VALTYPE_ 50 Cell12 : 1;
SIG_VALTYPE_ 50 Cell13 : 1;
SIG_VALTYPE_ 50 Cell14 : 1;
SIG_VALTYPE_ 50 Cell15 : 1;
SIG_VALTYPE_ 50 Cell16 : 1;
SIG_VALTYPE_ 51 Cell1 : 1;
SIG_VALTYPE_ 51 Cell2 : 1;
SIG_VALTYPE_ 51 Cell3 : 1;
SIG_VALTYPE_ 51 Cell4 : 1;
SIG_VALTYPE_ 51 Cell5 : 1;
SIG_VALTYPE_ 51 Cell6 : 1;
SIG_VALTYPE_ 51 Cell7 : 1;
SIG_VALTYPE_ 51 Cell8 : 1;
SIG_VALTYPE_ 51 Cell9 : 1;
SIG_VALTYPE_ 51 Cell10 : 1;
SIG_VALTYPE_ 51 Cell11 : 1;
SIG_VALTYPE_ 51 Cell12 : 1;
SIG_VALTYPE_ 51 Cell13 : 1;
SIG_VALTYPE_ 51 Cell14 : 1;
SIG_VALTYPE_ 51 Cell15 : 1;
SIG_VALTYPE_ 51 Cell16 : 1;
SIG_VALTYPE_ 52 Cell1 : 1;
SIG_VALTYPE_ 52 Cell2 : 1;
SIG_VALTYPE_ 52 Cell3 : 1;
SIG_VALTYPE_ 52 Cell4 : 1;
SIG_VALTYPE_ 52 Cell5 : 1;
SIG_VALTYPE_ 52 Cell6 : 1;
SIG_VALTYPE_ 52 Cell7 : 1;
SIG_VALTYPE_ 52 Cell8 : 1;
SIG_VALTYPE_ 52 Cell9 : 1;
SIG_VALTYPE_ 52 Cell10 : 1;
SIG_VALTYPE_ 52 Cell11 : 1;
SIG_VALTYPE_ 52 Cell12 : 1;
SIG_VALTYPE_ 52 Cell13 : 1;
SIG_VALTYPE_ 52 Cell14 : 1;
SIG_VALTYPE_ 52 Cell15 : 1;
SIG_VALTYPE_ 52 Cell16 : 1;
SIG_VALTYPE_ 53 Cell1 : 1;
SIG_VALTYPE_ 53 Cell2 : 1;
SIG_VALTYPE_ 53 Cell3 : 1;
SIG_VALTYPE_ 53 Cell4 : 1;
SIG_VALTYPE_ 53 Cell5 : 1;
SIG_VALTYPE_ 53 Cell6 : 1;
SIG_VALTYPE_ 53 Cell7 : 1;
SIG_VALTYPE_ 53 Cell8 : 1;
SIG_VALTYPE_ 53 Cell9 : 1;
SIG_VALTYPE_ 53 Cell10 : 1;
SIG_VALTYPE_ 53 Cell11 : 1;
SIG_VALTYPE_ 53 Cell12 : 1;
SIG_VALTYPE_ 53 Cell13 : 1;
SIG_VALTYPE_ 53 Cell14 : 1;
SIG_VALTYPE_ 53 Cell15 : 1;
SIG_VALTYPE_ 53 Cell16 : 1;
SIG_VALTYPE_ 54 Cell1 : 1;
SIG_VALTYPE_ 54 Cell2 : 1;
SIG_VALTYPE_ 54 Cell3 : 1;
SIG_VALTYPE_ 54 Cell4 : 1;
SIG_VALTYPE_ 54 Cell5 : 1;
SIG_VALTYPE_ 54 Cell6 : 1;
SIG_VALTYPE_ 54 Cell7 : 1;
SIG_VALTYPE_ 54 Cell8 : 1;
SIG_VALTYPE_ 54 Cell9 : 1;
SIG_VALTYPE_ 54 Cell10 : 1;
SIG_VALTYPE_ 54 Cell11 : 1;
SIG_VALTYPE_ 54 Cell12 : 1;
SIG_VALTYPE_ 54 Cell13 : 1;
SIG_VALTYPE_ 54 Cell14 : 1;
SIG_VALTYPE_ 54 Cell15 : 1;
SIG_VALTYPE_ 54 Cell16 : 1;
SIG_VALTYPE_ 55 Cell1 : 1;
SIG_VALTYPE_ 55 Cell2 : 1;
SIG_VALTYPE_ 55 Cell3 : 1;
SIG_VALTYPE_ 55 Cell4 : 1;
SIG_VALTYPE_ 55 Cell5 : 1;
SIG_VALTYPE_ 55 Cell6 : 1;
SIG_VALTYPE_ 55 Cell7 : 1;
SIG_VALTYPE_ 55 Cell8 : 1;
SIG_VALTYPE_ 55 Cell9 : 1;
SIG_VALTYPE_ 55 Cell10 : 1;
SIG_VALTYPE_ 55 Cell11 : 1;
SIG_VALTYPE_ 55 Cell12 : 1;
SIG_VALTYPE_ 55 Cell13 : 1;
SIG_VALTYPE_ 55 Cell14 : 1;
SIG_VALTYPE_ 55 Cell15 : 1;
SIG_VALTYPE_ 55 Cell16 : 1;
SIG_VALTYPE_ 56 Cell1 : 1;
SIG_VALTYPE_ 56 Cell2 : 1;
SIG_VALTYPE_ 56 Cell3 : 1;
SIG_VALTYPE_ 56 Cell4 : 1;
SIG_VALTYPE_ 56 Cell5 : 1;
SIG_VALTYPE_ 56 Cell6 : 1;
SIG_VALTYPE_ 56 Cell7 : 1;
SIG_VALTYPE_ 56 Cell8 : 1;
SIG_VALTYPE_ 56 Cell9 : 1;
SIG_VALTYPE_ 56 Cell10 : 1;
SIG_VALTYPE_ 56 Cell11 : 1;
SIG_VALTYPE_ 56 Cell12 : 1;
SIG_VALTYPE_ 56 Cell13 : 1;
SIG_VALTYPE_ 56 Cell14 : 1;
SIG_VALTYPE_ 56 Cell15 : 1;
SIG_VALTYPE_ 56 Cell16 : 1;
SIG_VALTYPE_ 57 Cell1 : 1;
SIG_VALTYPE_ 57 Cell2 : 1;
SIG_VALTYPE_ 57 Cell3 : 1;
SIG_VALTYPE_ 57 Cell4 : 1;
SIG_VALTYPE_ 57 Cell5 : 1;
SIG_VALTYPE_ 57 Cell6 : 1;
SIG_VALTYPE_ 57 Cell7 : 1;
SIG_VALTYPE_ 57 Cell8 : 1;
SIG_VALTYPE_ 57 Cell9 : 1;
SIG_VALTYPE_ 57 Cell10 : 1;
SIG_VALTYPE_ 57 Cell11 : 1;
SIG_VALTYPE_ 57 Cell12 : 1;
SIG_VALTYPE_ 57 Cell13 : 1;
SIG_VALTYPE_ 57 Cell14 : 1;
SIG_VALTYPE_ 57 Cell15 : 1;
SIG_VALTYPE_ 57 Cell16 : 1;
SIG_VALTYPE_ 60 Therm1 : 1;
SIG_VALTYPE_ 60 Therm2 : 1;
SIG_VALTYPE_ 60 Therm3 : 1;
SIG_VALTYPE_ 60 Therm4 : 1;
SIG_VALTYPE_ 60 Therm5 : 1;
SIG_VALTYPE_ 60 Therm6 : 1;
SIG_VALTYPE_ 60 Therm7 : 1;
SIG_VALTYPE_ 60 Therm8 : 1;
SIG_VALTYPE_ 60 Therm9 : 1;
SIG_VALTYPE_ 60 Therm10 : 1;
SIG_VALTYPE_ 60 Therm11 : 1;
SIG_VALTYPE_ 60 Therm12 : 1;
SIG_VALTYPE_ 60 Therm13 : 1;
SIG_VALTYPE_ 60 Therm14 : 1;
SIG_VALTYPE_ 60 Therm15 : 1;
SIG_VALTYPE_ 60 Therm16 : 1;
SIG_VALTYPE_ 61 Therm1 : 1;
SIG_VALTYPE_ 61 Therm2 : 1;
SIG_VALTYPE_ 61 Therm3 : 1;
SIG_VALTYPE_ 61 Therm4 : 1;
SIG_VALTYPE_ 61 Therm5 : 1;
SIG_VALTYPE_ 61 Therm6 : 1;
SIG_VALTYPE_ 61 Therm7 : 1;
SIG_VALTYPE_ 61 Therm8 : 1;
SIG_VALTYPE_ 61 Therm9 : 1;
SIG_VALTYPE_ 61 Therm10 : 1;
SIG_VALTYPE_ 61 Therm11 : 1;
SIG_VALTYPE_ 61 Therm12 : 1;
SIG_VALTYPE_ 61 Therm13 : 1;
SIG_VALTYPE_ 61 Therm14 : 1;
SIG_VALTYPE_ 61 Therm15 : 1;
SIG_VALTYPE_ 61 Therm16 : 1;
SIG_VALTYPE_ 62 Therm1 : 1;
SIG_VALTYPE_ 62 Therm2 : 1;
SIG_VALTYPE_ 62 Therm3 : 1;
SIG_VALTYPE_ 62 Therm4 : 1;
SIG_VALTYPE_ 62 Therm5 : 1;
SIG_VALTYPE_ 62 Therm6 : 1;
SIG_VALTYPE_ 62 Therm7 : 1;
SIG_VALTYPE_ 62 Therm8 : 1;
SIG_VALTYPE_ 62 Therm9 : 1;
SIG_VALTYPE_ 62 Therm10 : 1;
SIG_VALTYPE_ 62 Therm11 : 1;
SIG_VALTYPE_ 62 Therm12 : 1;
SIG_VALTYPE_ 62 Therm13 : 1;
SIG_VALTYPE_ 62 Therm14 : 1;
SIG_VALTYPE_ 62 Therm15 : 1;
SIG_VALTYPE_ 62 Therm16 : 1;
SIG_VALTYPE_ 63 Therm1 : 1;
SIG_VALTYPE_ 63 Therm2 : 1;
SIG_VALTYPE_ 63 Therm3 : 1;
SIG_VALTYPE_ 63 Therm4 : 1;
SIG_VALTYPE_ 63 Therm5 : 1;
SIG_VALTYPE_ 63 Therm6 : 1;
SIG_VALTYPE_ 63 Therm7 : 1;
SIG_VALTYPE_ 63 Therm8 : 1;
SIG_VALTYPE_ 63 Therm9 : 1;
SIG_VALTYPE_ 63 Therm10 : 1;
SIG_VALTYPE_ 63 Therm11 : 1;
SIG_VALTYPE_ 63 Therm12 : 1;
SIG_VALTYPE_ 63 Therm13 : 1;
SIG_VALTYPE_ 63 Therm14 : 1;
SIG_VALTYPE_ 63 Therm15 : 1;
SIG_VALTYPE_ 63 Therm16 : 1;
SIG_VALTYPE_ 64 Therm1 : 1;
SIG_VALTYPE_ 64 Therm2 : 1;
SIG_VALTYPE_ 64 Therm3 : 1;
SIG_VALTYPE_ 64 Therm4 : 1;
SIG_VALTYPE_ 64 Therm5 : 1;
SIG_VALTYPE_ 64 Therm6 : 1;
SIG_VALTYPE_ 64 Therm7 : 1;
SIG_VALTYPE_ 64 Therm8 : 1;
SIG_VALTYPE_ 64 Therm9 : 1;
SIG_VALTYPE_ 64 Therm10 : 1;
SIG_VALTYPE_ 64 Therm11 : 1;
SIG_VALTYPE_ 64 Therm12 : 1;
SIG_VALTYPE_ 64 Therm13 : 1;
SIG_VALTYPE_ 64 Therm14 : 1;
SIG_VALTYPE_ 64 Therm15 : 1;
SIG_VALTYPE_ 64 Therm16 : 1;
SIG_VALTYPE_ 65 Therm1 : 1;
SIG_VALTYPE_ 65 Therm2 : 1;
SIG_VALTYPE_ 65 Therm3 : 1;
SIG_VALTYPE_ 65 Therm4 : 1;
SIG_VALTYPE_ 65 Therm5 : 1;
SIG_VALTYPE_ 65 Therm6 : 1;
SIG_VALTYPE_ 65 Therm7 : 1;
SIG_VALTYPE_ 65 Therm8 : 1;
SIG_VALTYPE_ 65 Therm9 : 1;
SIG_VALTYPE_ 65 Therm10 : 1;
SIG_VALTYPE_ 65 Therm11 : 1;
SIG_VALTYPE_ 65 Therm12 : 1;
SIG_VALTYPE_ 65 Therm13 : 1;
SIG_VALTYPE_ 65 Therm14 : 1;
SIG_VALTYPE_ 65 Therm15 : 1;
SIG_VALTYPE_ 65 Therm16 : 1;
SIG_VALTYPE_ 66 Therm1 : 1;
SIG_VALTYPE_ 66 Therm2 : 1;
SIG_VALTYPE_ 66 Therm3 : 1;
SIG_VALTYPE_ 66 Therm4 : 1;
SIG_VALTYPE_ 66 Therm5 : 1;
SIG_VALTYPE_ 66 Therm6 : 1;
SIG_VALTYPE_ 66 Therm7 : 1;
SIG_VALTYPE_ 66 Therm8 : 1;
SIG_VALTYPE_ 66 Therm9 : 1;
SIG_VALTYPE_ 66 Therm10 : 1;
SIG_VALTYPE_ 66 Therm11 : 1;
SIG_VALTYPE_ 66 Therm12 : 1;
SIG_VALTYPE_ 66 Therm13 : 1;
SIG_VALTYPE_ 66 Therm14 : 1;
SIG_VALTYPE_ 66 Therm15 : 1;
SIG_VALTYPE_ 66 Therm16 : 1;
SIG_VALTYPE_ 67 Therm1 : 1;
SIG_VALTYPE_ 67 Therm2 : 1;
SIG_VALTYPE_ 67 Therm3 : 1;
SIG_VALTYPE_ 67 Therm4 : 1;
SIG_VALTYPE_ 67 Therm5 : 1;
SIG_VALTYPE_ 67 Therm6 : 1;
SIG_VALTYPE_ 67 Therm7 : 1;
SIG_VALTYPE_ 67 Therm8 : 1;
SIG_VALTYPE_ 67 Therm9 : 1;
SIG_VALTYPE_ 67 Therm10 : 1;
SIG_VALTYPE_ 67 Therm11 : 1;
SIG_VALTYPE_ 67 Therm12 : 1;
SIG_VALTYPE_ 67 Therm13 : 1;
SIG_VALTYPE_ 67 Therm14 : 1;
SIG_VALTYPE_ 67 Therm15 : 1;
SIG_VALTYPE_ 67 Therm16 : 1;
SIG_VALTYPE_ 68 Therm1 : 1;
SIG_VALTYPE_ 68 Therm2 : 1;
SIG_VALTYPE_ 68 Therm3 : 1;
SIG_VALTYPE_ 68 Therm4 : 1;
SIG_VALTYPE_ 68 Therm5 : 1;
SIG_VALTYPE_ 68 Therm6 : 1;
SIG_VALTYPE_ 68 Therm7 : 1;
SIG_VALTYPE_ 68 Therm8 : 1;
SIG_VALTYPE_ 68 Therm9 : 1;
SIG_VALTYPE_ 68 Therm10 : 1;
SIG_VALTYPE_ 68 Therm11 : 1;
SIG_VALTYPE_ 68 Therm12 : 1;
SIG_VALTYPE_ 68 Therm13 : 1;
SIG_VALTYPE_ 68 Therm14 : 1;
SIG_VALTYPE_ 68 Therm15 : 1;
SIG_VALTYPE_ 68 Therm16 : 1;
SIG_VALTYPE_ 69 Therm1 : 1;
SIG_VALTYPE_ 69 Therm2 : 1;
SIG_VALTYPE_ 69 Therm3 : 1;
SIG_VALTYPE_ 69 Therm4 : 1;
SIG_VALTYPE_ 69 Therm5 : 1;
SIG_VALTYPE_ 69 Therm6 : 1;
SIG_VALTYPE_ 69 Therm7 : 1;
SIG_VALTYPE_ 69 Therm8 : 1;
SIG_VALTYPE_ 69 Therm9 : 1;
SIG_VALTYPE_ 69 Therm10 : 1;
SIG_VALTYPE_ 69 Therm11 : 1;
SIG_VALTYPE_ 69 Therm12 : 1;
SIG_VALTYPE_ 69 Therm13 : 1;
SIG_VALTYPE_ 69 Therm14 : 1;
SIG_VALTYPE_ 69 Therm15 : 1;
SIG_VALTYPE_ 69 Therm16 : 1;
SIG_VALTYPE_ 70 Therm1 : 1;
SIG_VALTYPE_ 70 Therm2 : 1;
SIG_VALTYPE_ 70 Therm3 : 1;
SIG_VALTYPE_ 70 Therm4 : 1;
SIG_VALTYPE_ 70 Therm5 : 1;
SIG_VALTYPE_ 70 Therm6 : 1;
SIG_VALTYPE_ 70 Therm7 : 1;
SIG_VALTYPE_ 70 Therm8 : 1;
SIG_VALTYPE_ 70 Therm9 : 1;
SIG_VALTYPE_ 70 Therm10 : 1;
SIG_VALTYPE_ 70 Therm11 : 1;
SIG_VALTYPE_ 70 Therm12 : 1;
SIG_VALTYPE_ 70 Therm13 : 1;
SIG_VALTYPE_ 70 Therm14 : 1;
SIG_VALTYPE_ 70 Therm15 : 1;
SIG_VALTYPE_ 70 Therm16 : 1;
SIG_VALTYPE_ 71 Therm1 : 1;
SIG_VALTYPE_ 71 Therm2 : 1;
SIG_VALTYPE_ 71 Therm3 : 1;
SIG_VALTYPE_ 71 Therm4 : 1;
SIG_VALTYPE_ 71 Therm5 : 1;
SIG_VALTYPE_ 71 Therm6 : 1;
SIG_VALTYPE_ 71 Therm7 : 1;
SIG_VALTYPE_ 71 Therm8 : 1;
SIG_VALTYPE_ 71 Therm9 : 1;
SIG_VALTYPE_ 71 Therm10 : 1;
SIG_VALTYPE_ 71 Therm11 : 1;
SIG_VALTYPE_ 71 Therm12 : 1;
SIG_VALTYPE_ 71 Therm13 : 1;
SIG_VALTYPE_ 71 Therm14 : 1;
SIG_VALTYPE_ 71 Therm15 : 1;
SIG_VALTYPE_ 71 Therm16 : 1;
SIG_VALTYPE_ 5 PackVoltage : 1;
SIG_VALTYPE_ 6 APPS1 : 1;
SIG_VALTYPE_ 6 APPS2 : 1;
SIG_VALTYPE_ 6 BSE : 1;
SIG_VALTYPE_ 8 StateOfCharge : 1;
SIG_VALTYPE_ 8 AccumulatorVoltage : 1;
SIG_VALTYPE_ 8 TractiveVoltage : 1;
SIG_VALTYPE_ 8 CellCurrent : 1;
SIG_VALTYPE_ 8 IsolationMonitoring1 : 1;
SIG_VALTYPE_ 30 FanSetPoint : 1;
SIG_VALTYPE_ 30 RPM : 1;
SIG_VALTYPE_ 40 ChargeStatus1 : 1;
SIG_VALTYPE_ 40 ChargeStatus2 : 1;
SIG_VALTYPE_ 1280 PDMBattVoltage : 1;
SIG_VALTYPE_ 1280 InternalRailVoltage : 1;
